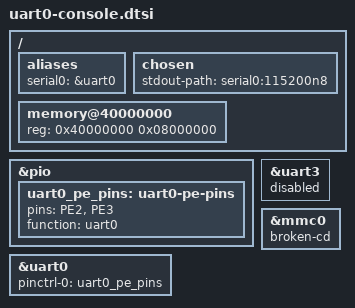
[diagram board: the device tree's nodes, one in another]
// uart0-console.dtsi — move the console UART from UART3 (PB6/PB7, the MangoPi
// MQ-R default) to UART0 (PE2/PE3), which is how the t113-breakout board wires
// its serial console.
//
// SHARED by BOTH stages — they each have their own device tree, but the tree is
// structurally identical (same serial3/uart3 default, same uart0/pio labels),
// so this one overlay serves both:
//   * U-Boot (01-uboot.sh) — its control DTB. U-Boot proper uses DM serial and
//     reads chosen/stdout-path; without this it would switch back to UART3 even
//     with CONFIG_CONS_INDEX=1 (which only fixes the SPL banner). Verified vs
//     U-Boot v2026.04 (arch/arm/mach-sunxi/board.c + serial-uclass.c).
//   * Linux kernel (02-kernel.sh) — its DTB. Sets serial0=&uart0 so Linux names
//     uart0 "ttyS0"; the kernel cmdline console must then be ttyS0 (KERNEL_CONSOLE).
//     Verified vs kernel v6.12.95 (same DTS layout).
//
// Each step #includes this into the board .dts before building. Node labels
// (uart0 = serial@2500000, uart3, pio) exist in the shared sunxi-d1s-t113.dtsi
// in both trees; uart0 ships status="disabled" and no uart0 pin group exists
// upstream — so we define uart0_pe_pins ourselves.

/ {
	aliases {
		/* U-Boot resolves stdout-path "serial0" through this alias. */
		serial0 = &uart0;
	};

	chosen {
		stdout-path = "serial0:115200n8";
		/*
		 * NO bootargs here — intentionally. The command line is set at boot
		 * by whichever loader runs: U-Boot's boot.scr does `fdt set /chosen
		 * bootargs ...`, and our custom bootloader's fdt_set_bootargs() now
		 * grows/inserts the property properly (see bootloader/fdt.c). Leaving
		 * bootargs absent keeps this a clean, stock-shaped chosen node and
		 * avoids the "placeholder shadows the real cmdline" trap that once
		 * silently booted the kernel with no console=.
		 */
	};

	/*
	 * Memory node: 128 MiB DDR3 at 0x40000000. U-Boot normally fills this
	 * in at boot from the SPL-detected size; our custom bootloader does not,
	 * so we state it here. #address-cells/#size-cells are 1 at the root, so
	 * reg is a single <base size> pair of 32-bit cells.
	 * (Harmless under U-Boot, which overwrites the memory node anyway.)
	 */
	memory@40000000 {
		device_type = "memory";
		reg = <0x40000000 0x08000000>;   /* 128 MiB */
	};
};

/* Add the PE2/PE3 pinmux group under the pin controller. function="uart0"
 * matches the sunxi pinctrl driver's UART0 mux (same as SPL mux func 6). */
&pio {
	uart0_pe_pins: uart0-pe-pins {
		pins = "PE2", "PE3";
		function = "uart0";
	};
};

/* Enable UART0 and bind it to the PE pins. */
&uart0 {
	pinctrl-names = "default";
	pinctrl-0 = <&uart0_pe_pins>;
	status = "okay";
};

/* Drop UART3 from the console path. Leaving it enabled is harmless, but our
 * board does not use it and disabling keeps the console unambiguous. */
&uart3 {
	status = "disabled";
};

/* --- microSD card-detect fix (t113-breakout) -------------------------------
 * The MangoPi MQ-R DT declares the SD socket's card-detect on cd-gpios =
 * <&pio 5 6> (PF6, active-low). On our t113-breakout, PF6 is broken out as a
 * plain free GPIO and the SD socket's card-detect (socket pin 9) is left
 * UNCONNECTED (BOM: "card-detect available → wire to a spare GPIO if wanted").
 * So U-Boot/Linux read PF6, see it high, and declare "no card present" —
 * refusing to scan mmc0 even with a card seated (the BROM boots fine because it
 * ignores DT and CD). Verified on silicon: SPL boots from SD, but U-Boot proper
 * then reports `Card did not respond to voltage select! : -110` / "no card
 * present" on mmc0/mmc dev 1.
 *
 * Fix: delete the bogus cd-gpios and mark the slot broken-cd so the MMC driver
 * always assumes a card is present and polls it. (Same overlay is shared by the
 * U-Boot control DTB and the kernel DTB, so both get the fix.)
 */
&mmc0 {
	/delete-property/ cd-gpios;
	broken-cd;
};
